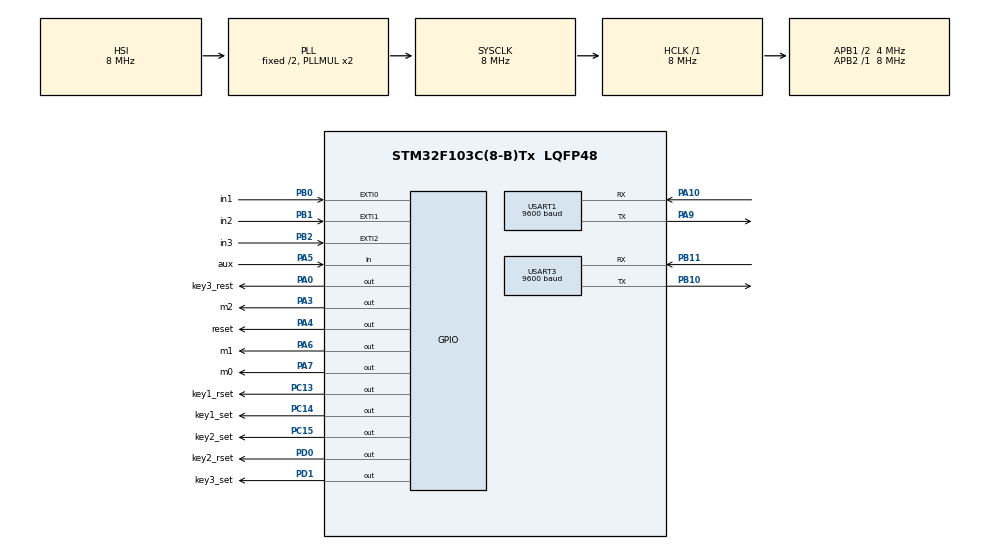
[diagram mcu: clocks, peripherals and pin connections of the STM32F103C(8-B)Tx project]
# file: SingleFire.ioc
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Dma.Request0=USART1_RX
Dma.Request1=USART1_TX
Dma.Request2=USART3_RX
Dma.Request3=USART3_TX
Dma.USART1_RX.0.Direction=DMA_PERIPH_TO_MEMORY
Dma.USART1_RX.0.Instance=DMA1_Channel5
Dma.USART1_RX.0.MemDataAlignment=DMA_MDATAALIGN_BYTE
Dma.USART1_RX.0.MemInc=DMA_MINC_ENABLE
Dma.USART1_RX.0.Mode=DMA_NORMAL
Dma.USART1_RX.0.PeriphDataAlignment=DMA_PDATAALIGN_BYTE
Dma.USART1_RX.0.PeriphInc=DMA_PINC_DISABLE
Dma.USART1_RX.0.Priority=DMA_PRIORITY_LOW
Dma.USART1_TX.1.Direction=DMA_MEMORY_TO_PERIPH
Dma.USART1_TX.1.Instance=DMA1_Channel4
Dma.USART1_TX.1.MemDataAlignment=DMA_MDATAALIGN_BYTE
Dma.USART1_TX.1.MemInc=DMA_MINC_ENABLE
Dma.USART1_TX.1.Mode=DMA_NORMAL
Dma.USART1_TX.1.PeriphDataAlignment=DMA_PDATAALIGN_BYTE
Dma.USART1_TX.1.PeriphInc=DMA_PINC_DISABLE
Dma.USART1_TX.1.Priority=DMA_PRIORITY_LOW
Dma.USART3_RX.2.Direction=DMA_PERIPH_TO_MEMORY
Dma.USART3_RX.2.Instance=DMA1_Channel3
Dma.USART3_RX.2.MemDataAlignment=DMA_MDATAALIGN_BYTE
Dma.USART3_RX.2.MemInc=DMA_MINC_ENABLE
Dma.USART3_RX.2.Mode=DMA_NORMAL
Dma.USART3_RX.2.PeriphDataAlignment=DMA_PDATAALIGN_BYTE
Dma.USART3_RX.2.PeriphInc=DMA_PINC_DISABLE
Dma.USART3_RX.2.Priority=DMA_PRIORITY_LOW
Dma.USART3_TX.3.Direction=DMA_MEMORY_TO_PERIPH
Dma.USART3_TX.3.Instance=DMA1_Channel2
Dma.USART3_TX.3.MemDataAlignment=DMA_MDATAALIGN_BYTE
Dma.USART3_TX.3.MemInc=DMA_MINC_ENABLE
Dma.USART3_TX.3.Mode=DMA_NORMAL
Dma.USART3_TX.3.PeriphDataAlignment=DMA_PDATAALIGN_BYTE
Dma.USART3_TX.3.PeriphInc=DMA_PINC_DISABLE
Dma.USART3_TX.3.Priority=DMA_PRIORITY_LOW
Mcu.Family=STM32F1
Mcu.Name=STM32F103C(8-B)Tx
Mcu.Package=LQFP48
NVIC.DMA1_Channel2_IRQn=true\:0\:0\:false\:false\:true\:false
NVIC.DMA1_Channel3_IRQn=true\:0\:0\:false\:false\:true\:false
NVIC.DMA1_Channel4_IRQn=true\:0\:0\:false\:false\:true\:false
NVIC.DMA1_Channel5_IRQn=true\:0\:0\:false\:false\:true\:false
NVIC.EXTI0_IRQn=true\:4\:0\:true\:false\:true\:true
NVIC.EXTI1_IRQn=true\:4\:0\:true\:false\:true\:true
NVIC.EXTI2_IRQn=true\:4\:0\:true\:false\:true\:true
NVIC.PriorityGroup=NVIC_PRIORITYGROUP_4
NVIC.USART1_IRQn=true\:0\:0\:false\:false\:true\:true
NVIC.USART3_IRQn=true\:0\:0\:false\:false\:true\:true
PA0-WKUP.GPIO_Label=key3_rest
PA0-WKUP.PinState=GPIO_PIN_RESET
PA0-WKUP.Signal=GPIO_Output
PA10.Mode=Asynchronous
PA10.Signal=USART1_RX
PA13.Mode=Serial_Wire
PA13.Signal=SYS_JTMS-SWDIO
PA14.Mode=Serial_Wire
PA14.Signal=SYS_JTCK-SWCLK
PA3.GPIO_Label=m2
PA3.PinState=GPIO_PIN_SET
PA3.Signal=GPIO_Output
PA4.GPIO_Label=reset
PA4.PinState=GPIO_PIN_SET
PA4.Signal=GPIO_Output
PA5.GPIO_Label=aux
PA5.Signal=GPIO_Input
PA6.GPIO_Label=m1
PA6.PinState=GPIO_PIN_SET
PA6.Signal=GPIO_Output
PA7.GPIO_Label=m0
PA7.Signal=GPIO_Output
PA9.Mode=Asynchronous
PA9.Signal=USART1_TX
PB0.GPIO_Label=in1
PB0.GPIO_ModeDefaultEXTI=GPIO_MODE_IT_RISING_FALLING
PB0.Signal=GPXTI0
PB1.GPIO_Label=in2
PB1.GPIO_ModeDefaultEXTI=GPIO_MODE_IT_RISING_FALLING
PB1.Signal=GPXTI1
PB10.Mode=Asynchronous
PB10.Signal=USART3_TX
PB11.Mode=Asynchronous
PB11.Signal=USART3_RX
PB2.GPIO_Label=in3
PB2.GPIO_ModeDefaultEXTI=GPIO_MODE_IT_RISING_FALLING
PB2.Signal=GPXTI2
PC13-TAMPER-RTC.GPIO_Label=key1_rset
PC13-TAMPER-RTC.PinState=GPIO_PIN_RESET
PC13-TAMPER-RTC.Signal=GPIO_Output
PC14-OSC32_IN.GPIO_Label=key1_set
PC14-OSC32_IN.PinState=GPIO_PIN_RESET
PC14-OSC32_IN.Signal=GPIO_Output
PC15-OSC32_OUT.GPIO_Label=key2_set
PC15-OSC32_OUT.PinState=GPIO_PIN_RESET
PC15-OSC32_OUT.Signal=GPIO_Output
PD0-OSC_IN.GPIO_Label=key2_rset
PD0-OSC_IN.PinState=GPIO_PIN_RESET
PD0-OSC_IN.Signal=GPIO_Output
PD1-OSC_OUT.GPIO_Label=key3_set
PD1-OSC_OUT.PinState=GPIO_PIN_RESET
PD1-OSC_OUT.Signal=GPIO_Output
ProjectManager.HeapSize=0x200
ProjectManager.StackSize=0x400
ProjectManager.TargetToolchain=SW4STM32
RCC.AHBFreq_Value=8000000
RCC.APB1CLKDivider=RCC_HCLK_DIV2
RCC.APB1Freq_Value=4000000
RCC.APB1TimFreq_Value=8000000
RCC.APB2Freq_Value=8000000
RCC.APB2TimFreq_Value=8000000
RCC.HCLKFreq_Value=8000000
RCC.SYSCLKFreq_VALUE=8000000
RCC.SYSCLKSource=RCC_SYSCLKSOURCE_PLLCLK
RCC.USBFreq_Value=8000000
USART1.BaudRate=9600
USART1.VirtualMode=VM_ASYNC
USART3.BaudRate=9600
USART3.VirtualMode=VM_ASYNC
board=SingleFire

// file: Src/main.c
/**
  ******************************************************************************
  * @file           : main.c
  * @brief          : Main program body
  ******************************************************************************
  ** This notice applies to any and all portions of this file
  * that are not between comment pairs USER CODE BEGIN and
  * USER CODE END. Other portions of this file, whether
  * inserted by the user or by software development tools
  * are owned by their respective copyright owners.
  *
  * COPYRIGHT(c) 2018 STMicroelectronics
  *
  * Redistribution and use in source and binary forms, with or without modification,
  * are permitted provided that the following conditions are met:
  *   1. Redistributions of source code must retain the above copyright notice,
  *      this list of conditions and the following disclaimer.
  *   2. Redistributions in binary form must reproduce the above copyright notice,
  *      this list of conditions and the following disclaimer in the documentation
  *      and/or other materials provided with the distribution.
  *   3. Neither the name of STMicroelectronics nor the names of its contributors
  *      may be used to endorse or promote products derived from this software
  *      without specific prior written permission.
  *
  * THIS SOFTWARE IS PROVIDED BY THE COPYRIGHT HOLDERS AND CONTRIBUTORS "AS IS"
  * AND ANY EXPRESS OR IMPLIED WARRANTIES, INCLUDING, BUT NOT LIMITED TO, THE
  * IMPLIED WARRANTIES OF MERCHANTABILITY AND FITNESS FOR A PARTICULAR PURPOSE ARE
  * DISCLAIMED. IN NO EVENT SHALL THE COPYRIGHT HOLDER OR CONTRIBUTORS BE LIABLE
  * FOR ANY DIRECT, INDIRECT, INCIDENTAL, SPECIAL, EXEMPLARY, OR CONSEQUENTIAL
  * DAMAGES (INCLUDING, BUT NOT LIMITED TO, PROCUREMENT OF SUBSTITUTE GOODS OR
  * SERVICES; LOSS OF USE, DATA, OR PROFITS; OR BUSINESS INTERRUPTION) HOWEVER
  * CAUSED AND ON ANY THEORY OF LIABILITY, WHETHER IN CONTRACT, STRICT LIABILITY,
  * OR TORT (INCLUDING NEGLIGENCE OR OTHERWISE) ARISING IN ANY WAY OUT OF THE USE
  * OF THIS SOFTWARE, EVEN IF ADVISED OF THE POSSIBILITY OF SUCH DAMAGE.
  *
  ******************************************************************************
  */
#include "main.h"
#include "stm32f1xx_hal.h"
#include "dma.h"
#include "usart.h"
#include "gpio.h"

/* USER CODE BEGIN Includes */
#include "dataProcessing.h"
/* USER CODE END Includes */

/* USER CODE BEGIN PV */
/* Private variables ---------------------------------------------------------*/

/* USER CODE END PV */

void SystemClock_Config(void);

/* USER CODE BEGIN PFP */
/* Private function prototypes -----------------------------------------------*/

/* USER CODE END PFP */

int main(void)
{

  /* MCU Configuration----------------------------------------------------------*/

  /* Reset of all peripherals, Initializes the Flash interface and the Systick. */
  HAL_Init();

  /* Configure the system clock */
  SystemClock_Config();

  /* USER CODE BEGIN SysInit */
  __HAL_RCC_PWR_CLK_ENABLE();
  /* USER CODE END SysInit */

  /* Initialize all configured peripherals */
  MX_GPIO_Init();
  MX_DMA_Init();
  MX_USART3_UART_Init();
  MX_USART1_UART_Init();
  /* USER CODE BEGIN 2 */
  if (HAL_UART_Receive_DMA(&huart1, (uint8_t *)&usart1_rx_buffer, 128) != HAL_OK)    Error_Handler();
  if (HAL_UART_Receive_DMA(&huart3, (uint8_t *)&usart3_rx_buffer, 128) != HAL_OK)    Error_Handler();
  __HAL_UART_ENABLE_IT(&huart1, UART_IT_IDLE);
  __HAL_UART_ENABLE_IT(&huart3, UART_IT_IDLE);
  /* USER CODE END 2 */

  /* Infinite loop */
  while (1)
  {

  /* USER CODE BEGIN 3 */

	  dataProcessing();
	  /*挂起滴答定时器增加以避免滴答定时器中断唤醒睡眠模式*/
	  HAL_SuspendTick();

	  /*进入睡眠模式，等待中断唤醒*/
	  HAL_PWR_EnterSLEEPMode(PWR_MAINREGULATOR_ON, PWR_SLEEPENTRY_WFI);

	  /*退出睡眠模式之后，释放滴答定时器中断*/
	  HAL_ResumeTick();
  }
  /* USER CODE END 3 */

}

void SystemClock_Config(void)
{

  RCC_OscInitTypeDef RCC_OscInitStruct;
  RCC_ClkInitTypeDef RCC_ClkInitStruct;

    /**Initializes the CPU, AHB and APB busses clocks
    */
  RCC_OscInitStruct.OscillatorType = RCC_OSCILLATORTYPE_HSI;
  RCC_OscInitStruct.HSIState = RCC_HSI_ON;
  RCC_OscInitStruct.HSICalibrationValue = 16;
  RCC_OscInitStruct.PLL.PLLState = RCC_PLL_ON;
  RCC_OscInitStruct.PLL.PLLSource = RCC_PLLSOURCE_HSI_DIV2;
  RCC_OscInitStruct.PLL.PLLMUL = RCC_PLL_MUL2;
  if (HAL_RCC_OscConfig(&RCC_OscInitStruct) != HAL_OK)
  {
    _Error_Handler(__FILE__, __LINE__);
  }

    /**Initializes the CPU, AHB and APB busses clocks
    */
  RCC_ClkInitStruct.ClockType = RCC_CLOCKTYPE_HCLK|RCC_CLOCKTYPE_SYSCLK
                              |RCC_CLOCKTYPE_PCLK1|RCC_CLOCKTYPE_PCLK2;
  RCC_ClkInitStruct.SYSCLKSource = RCC_SYSCLKSOURCE_PLLCLK;
  RCC_ClkInitStruct.AHBCLKDivider = RCC_SYSCLK_DIV1;
  RCC_ClkInitStruct.APB1CLKDivider = RCC_HCLK_DIV2;
  RCC_ClkInitStruct.APB2CLKDivider = RCC_HCLK_DIV1;

  if (HAL_RCC_ClockConfig(&RCC_ClkInitStruct, FLASH_LATENCY_0) != HAL_OK)
  {
    _Error_Handler(__FILE__, __LINE__);
  }

    /**Configure the Systick interrupt time
    */
  HAL_SYSTICK_Config(HAL_RCC_GetHCLKFreq()/1000);

    /**Configure the Systick
    */
  HAL_SYSTICK_CLKSourceConfig(SYSTICK_CLKSOURCE_HCLK);

  /* SysTick_IRQn interrupt configuration */
  HAL_NVIC_SetPriority(SysTick_IRQn, 0, 0);
}

void _Error_Handler(char *file, int line)
{
  while(1)
  {
  }
}

/************************ (C) COPYRIGHT STMicroelectronics *****END OF FILE****/
